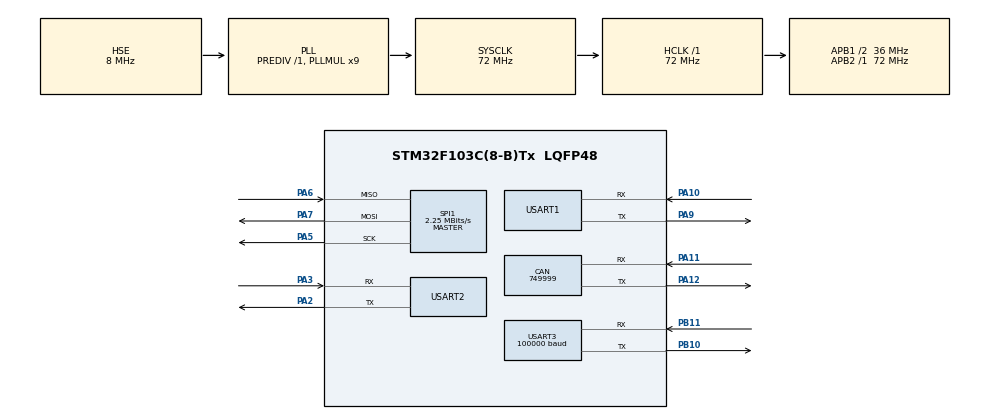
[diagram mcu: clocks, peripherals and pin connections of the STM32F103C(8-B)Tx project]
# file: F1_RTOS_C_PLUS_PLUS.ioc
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CAN.CalculateBaudRate=749999
CAN.CalculateTimeBit=1333
CAN.CalculateTimeQuantum=444.44444444444446
Dma.Request0=USART2_RX
Dma.Request1=USART3_RX
Dma.USART2_RX.0.Direction=DMA_PERIPH_TO_MEMORY
Dma.USART2_RX.0.Instance=DMA1_Channel6
Dma.USART2_RX.0.MemDataAlignment=DMA_MDATAALIGN_BYTE
Dma.USART2_RX.0.MemInc=DMA_MINC_ENABLE
Dma.USART2_RX.0.Mode=DMA_NORMAL
Dma.USART2_RX.0.PeriphDataAlignment=DMA_PDATAALIGN_BYTE
Dma.USART2_RX.0.PeriphInc=DMA_PINC_DISABLE
Dma.USART2_RX.0.Priority=DMA_PRIORITY_LOW
Dma.USART3_RX.1.Direction=DMA_PERIPH_TO_MEMORY
Dma.USART3_RX.1.Instance=DMA1_Channel3
Dma.USART3_RX.1.MemDataAlignment=DMA_MDATAALIGN_BYTE
Dma.USART3_RX.1.MemInc=DMA_MINC_ENABLE
Dma.USART3_RX.1.Mode=DMA_NORMAL
Dma.USART3_RX.1.PeriphDataAlignment=DMA_PDATAALIGN_BYTE
Dma.USART3_RX.1.PeriphInc=DMA_PINC_DISABLE
Dma.USART3_RX.1.Priority=DMA_PRIORITY_LOW
FREERTOS.INCLUDE_vTaskDelayUntil=1
FREERTOS.Tasks01=defaultTask,0,128,StartDefaultTask,Default,NULL,Dynamic,NULL,NULL
Mcu.Family=STM32F1
Mcu.Name=STM32F103C(8-B)Tx
Mcu.Package=LQFP48
NVIC.DMA1_Channel3_IRQn=true\:5\:0\:false\:false\:true\:true\:false\:true\:true
NVIC.DMA1_Channel6_IRQn=true\:5\:0\:false\:false\:true\:true\:false\:true\:true
NVIC.PriorityGroup=NVIC_PRIORITYGROUP_4
NVIC.TIM4_IRQn=true\:15\:0\:false\:false\:true\:false\:false\:true\:true
NVIC.TimeBase=TIM4_IRQn
NVIC.TimeBaseIP=TIM4
NVIC.USART3_IRQn=true\:4\:0\:true\:false\:true\:false\:true\:true\:true
NVIC.USB_LP_CAN1_RX0_IRQn=true\:5\:0\:false\:false\:true\:true\:true\:true\:true
PA10.Mode=Asynchronous
PA10.Signal=USART1_RX
PA11.Mode=CAN_Activate
PA11.Signal=CAN_RX
PA12.Mode=CAN_Activate
PA12.Signal=CAN_TX
PA13.Mode=Serial_Wire
PA13.Signal=SYS_JTMS-SWDIO
PA14.Mode=Serial_Wire
PA14.Signal=SYS_JTCK-SWCLK
PA2.Mode=Asynchronous
PA2.Signal=USART2_TX
PA3.Mode=Asynchronous
PA3.Signal=USART2_RX
PA5.Mode=Full_Duplex_Master
PA5.Signal=SPI1_SCK
PA6.Mode=Full_Duplex_Master
PA6.Signal=SPI1_MISO
PA7.Mode=Full_Duplex_Master
PA7.Signal=SPI1_MOSI
PA9.Mode=Asynchronous
PA9.Signal=USART1_TX
PB10.Mode=Asynchronous
PB10.Signal=USART3_TX
PB11.Mode=Asynchronous
PB11.Signal=USART3_RX
PD0-OSC_IN.Mode=HSE-External-Oscillator
PD0-OSC_IN.Signal=RCC_OSC_IN
PD1-OSC_OUT.Mode=HSE-External-Oscillator
PD1-OSC_OUT.Signal=RCC_OSC_OUT
ProjectManager.HeapSize=0x200
ProjectManager.StackSize=0x400
ProjectManager.TargetToolchain=MDK-ARM V5.32
RCC.AHBFreq_Value=72000000
RCC.APB1CLKDivider=RCC_HCLK_DIV2
RCC.APB1Freq_Value=36000000
RCC.APB1TimFreq_Value=72000000
RCC.APB2Freq_Value=72000000
RCC.APB2TimFreq_Value=72000000
RCC.HCLKFreq_Value=72000000
RCC.PLLMUL=RCC_PLL_MUL9
RCC.PLLSourceVirtual=RCC_PLLSOURCE_HSE
RCC.SYSCLKFreq_VALUE=72000000
RCC.SYSCLKSource=RCC_SYSCLKSOURCE_PLLCLK
RCC.USBFreq_Value=72000000
SPI1.BaudRatePrescaler=SPI_BAUDRATEPRESCALER_32
SPI1.CalculateBaudRate=2.25 MBits/s
SPI1.Direction=SPI_DIRECTION_2LINES
SPI1.Mode=SPI_MODE_MASTER
SPI1.VirtualType=VM_MASTER
STMicroelectronics.X-CUBE-ALGOBUILD.1.3.0.LibraryCcDSPOoLibraryJjDSPOoLibrary=true
USART1.VirtualMode=VM_ASYNC
USART2.VirtualMode=VM_ASYNC
USART3.BaudRate=100000
USART3.VirtualMode=VM_ASYNC
USART3.WordLength=WORDLENGTH_9B
VP_FREERTOS_VS_CMSIS_V1.Mode=CMSIS_V1
VP_STMicroelectronics.X-CUBE-ALGOBUILD_VS_DSPOoLibraryJjLibrary_1.3.0_1.3.0.Mode=DSPOoLibraryJjLibrary
VP_SYS_VS_tim4.Mode=TIM4
VP_TIM1_VS_ClockSourceINT.Mode=Internal
board=custom

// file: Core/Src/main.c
/* USER CODE BEGIN Header */
/**
  ******************************************************************************
  * @file           : main.c
  * @brief          : Main program body
  ******************************************************************************
  * @attention
  *
  * Copyright (c) 2024 STMicroelectronics.
  * All rights reserved.
  *
  * This software is licensed under terms that can be found in the LICENSE file
  * in the root directory of this software component.
  * If no LICENSE file comes with this software, it is provided AS-IS.
  *
  ******************************************************************************
  */
/* USER CODE END Header */
#include "main.h"
#include "cmsis_os.h"
#include "can.h"
#include "dma.h"
#include "spi.h"
#include "tim.h"
#include "usart.h"
#include "gpio.h"

/* USER CODE BEGIN Includes */
#include "RM_Lib.hpp"
/* USER CODE END Includes */

/* USER CODE BEGIN PV */
extern "C"{
/* USER CODE END PV */

void SystemClock_Config(void);
void MX_FREERTOS_Init(void);
}

int main(void)
{

  /* MCU Configuration--------------------------------------------------------*/

  /* Reset of all peripherals, Initializes the Flash interface and the Systick. */
  HAL_Init();

  /* Configure the system clock */
  SystemClock_Config();

  /* Initialize all configured peripherals */
  MX_GPIO_Init();
  MX_DMA_Init();
  MX_CAN_Init();
  MX_SPI1_Init();
  MX_TIM1_Init();
  MX_USART1_UART_Init();
  MX_USART2_UART_Init();
  MX_USART3_UART_Init();

  /* Call init function for freertos objects (in freertos.c) */
  MX_FREERTOS_Init();

  /* Start scheduler */
  osKernelStart();

  /* We should never get here as control is now taken by the scheduler */
  /* Infinite loop */
  while (1)
  {

  }
}

void SystemClock_Config(void)
{
  RCC_OscInitTypeDef RCC_OscInitStruct = {0};
  RCC_ClkInitTypeDef RCC_ClkInitStruct = {0};

  /** Initializes the RCC Oscillators according to the specified parameters
  * in the RCC_OscInitTypeDef structure.
  */
  RCC_OscInitStruct.OscillatorType = RCC_OSCILLATORTYPE_HSE;
  RCC_OscInitStruct.HSEState = RCC_HSE_ON;
  RCC_OscInitStruct.HSEPredivValue = RCC_HSE_PREDIV_DIV1;
  RCC_OscInitStruct.HSIState = RCC_HSI_ON;
  RCC_OscInitStruct.PLL.PLLState = RCC_PLL_ON;
  RCC_OscInitStruct.PLL.PLLSource = RCC_PLLSOURCE_HSE;
  RCC_OscInitStruct.PLL.PLLMUL = RCC_PLL_MUL9;
  if (HAL_RCC_OscConfig(&RCC_OscInitStruct) != HAL_OK)
  {
    Error_Handler();
  }

  /** Initializes the CPU, AHB and APB buses clocks
  */
  RCC_ClkInitStruct.ClockType = RCC_CLOCKTYPE_HCLK|RCC_CLOCKTYPE_SYSCLK
                              |RCC_CLOCKTYPE_PCLK1|RCC_CLOCKTYPE_PCLK2;
  RCC_ClkInitStruct.SYSCLKSource = RCC_SYSCLKSOURCE_PLLCLK;
  RCC_ClkInitStruct.AHBCLKDivider = RCC_SYSCLK_DIV1;
  RCC_ClkInitStruct.APB1CLKDivider = RCC_HCLK_DIV2;
  RCC_ClkInitStruct.APB2CLKDivider = RCC_HCLK_DIV1;

  if (HAL_RCC_ClockConfig(&RCC_ClkInitStruct, FLASH_LATENCY_2) != HAL_OK)
  {
    Error_Handler();
  }
}

void HAL_TIM_PeriodElapsedCallback(TIM_HandleTypeDef *htim)
{
  if (htim->Instance == TIM4) {
    HAL_IncTick();
  }
}

void Error_Handler(void)
{
  __disable_irq();
  while (1)
  {
  }
}

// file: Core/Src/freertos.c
/* USER CODE BEGIN Header */
/**
  ******************************************************************************
  * File Name          : freertos.c
  * Description        : Code for freertos applications
  ******************************************************************************
  * @attention
  *
  * Copyright (c) 2024 STMicroelectronics.
  * All rights reserved.
  *
  * This software is licensed under terms that can be found in the LICENSE file
  * in the root directory of this software component.
  * If no LICENSE file comes with this software, it is provided AS-IS.
  *
  ******************************************************************************
  */
/* USER CODE END Header */

#include "FreeRTOS.h"
#include "task.h"
#include "main.h"
#include "cmsis_os.h"

osThreadId defaultTaskHandle;

/* USER CODE BEGIN FunctionPrototypes */
extern "C"{
/* USER CODE END FunctionPrototypes */

void StartDefaultTask(void const * argument);

void MX_FREERTOS_Init(void); /* (MISRA C 2004 rule 8.1) */

/* GetIdleTaskMemory prototype (linked to static allocation support) */
void vApplicationGetIdleTaskMemory( StaticTask_t **ppxIdleTaskTCBBuffer, StackType_t **ppxIdleTaskStackBuffer, uint32_t *pulIdleTaskStackSize );

/* USER CODE BEGIN GET_IDLE_TASK_MEMORY */
}
static StaticTask_t xIdleTaskTCBBuffer;
static StackType_t xIdleStack[configMINIMAL_STACK_SIZE];

void vApplicationGetIdleTaskMemory( StaticTask_t **ppxIdleTaskTCBBuffer, StackType_t **ppxIdleTaskStackBuffer, uint32_t *pulIdleTaskStackSize )
{
  *ppxIdleTaskTCBBuffer = &xIdleTaskTCBBuffer;
  *ppxIdleTaskStackBuffer = &xIdleStack[0];
  *pulIdleTaskStackSize = configMINIMAL_STACK_SIZE;
  /* place for user code */
}
/* USER CODE END GET_IDLE_TASK_MEMORY */

void MX_FREERTOS_Init(void) {

  /* Create the thread(s) */
  /* definition and creation of defaultTask */
  osThreadDef(defaultTask, StartDefaultTask, osPriorityNormal, 0, 128);
  defaultTaskHandle = osThreadCreate(osThread(defaultTask), NULL);

}

void StartDefaultTask(void const * argument)
{
  for(;;)
  {
    osDelay(1);
  }
}
